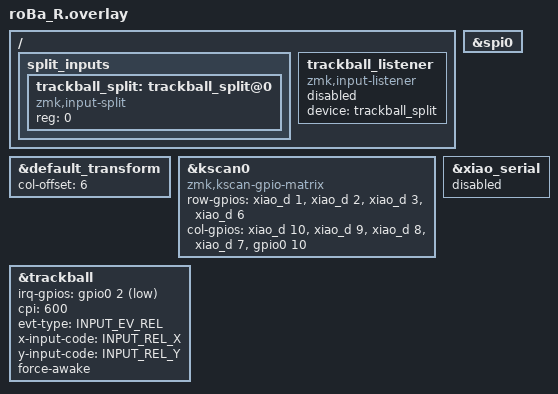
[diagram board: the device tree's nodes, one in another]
#include "roBa.dtsi"
#include "roBa_trackball.dtsi"



&default_transform {
    col-offset = <6>;
};


&kscan0 {
  compatible = "zmk,kscan-gpio-matrix";
     row-gpios
        = <&xiao_d 1 (GPIO_ACTIVE_HIGH | GPIO_PULL_DOWN)> 
        , <&xiao_d 2 (GPIO_ACTIVE_HIGH | GPIO_PULL_DOWN)> 
        , <&xiao_d 3 (GPIO_ACTIVE_HIGH | GPIO_PULL_DOWN)> 
        , <&xiao_d 6 (GPIO_ACTIVE_HIGH | GPIO_PULL_DOWN)> 			
        ;

     col-gpios
        = <&xiao_d 10 GPIO_ACTIVE_HIGH>
         , <&xiao_d 9 GPIO_ACTIVE_HIGH> 
        , <&xiao_d 8 GPIO_ACTIVE_HIGH> 
        , <&xiao_d 7 GPIO_ACTIVE_HIGH> 
        , <&gpio0 10 GPIO_ACTIVE_HIGH>
        ;
};

&spi0 {
    status = "okay";
};

&trackball {
    status = "okay";
	irq-gpios = <&gpio0 2 (GPIO_ACTIVE_LOW | GPIO_PULL_UP)>;
	cpi = <600>;
	evt-type = <INPUT_EV_REL>;
	x-input-code = <INPUT_REL_X>;
	y-input-code = <INPUT_REL_Y>;
    force-awake;
};


/*input-split*/
/ {
    split_inputs {
        #address-cells = <1>;
        #size-cells = <0>;

        trackball_split: trackball_split@0 {
            compatible = "zmk,input-split";
            reg = <0>;
        };
    };

    trackball_listener: trackball_listener {
        compatible = "zmk,input-listener";
        status = "disabled";
        device = <&trackball_split>;
    };
};

&xiao_serial { status = "disabled"; };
